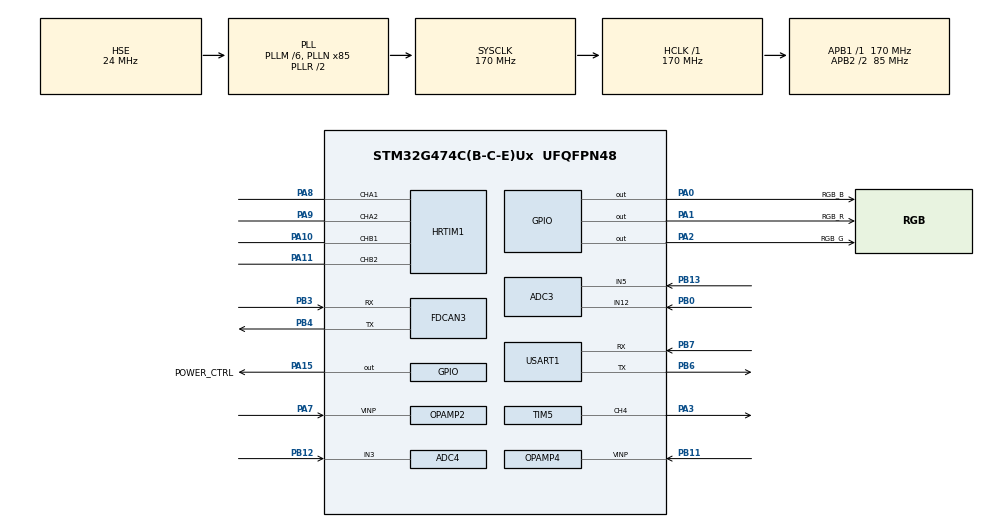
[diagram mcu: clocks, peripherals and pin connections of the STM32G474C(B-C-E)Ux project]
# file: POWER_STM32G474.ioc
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ADC2.Channel-3\#ChannelRegularConversion=ADC_CHANNEL_VOPAMP2
ADC2.ClockPrescaler=ADC_CLOCK_ASYNC_DIV16
ADC2.ContinuousConvMode=DISABLE
ADC2.DMAContinuousRequests=ENABLE
ADC2.ExternalTrigConv=ADC_EXTERNALTRIG_HRTIM_TRG1
ADC2.NbrOfConversion=1
ADC2.NbrOfConversionFlag=1
ADC2.OffsetNumber-3\#ChannelRegularConversion=ADC_OFFSET_NONE
ADC2.OversamplingMode=ENABLE
ADC2.Rank-3\#ChannelRegularConversion=1
ADC2.Ratio=ADC_OVERSAMPLING_RATIO_32
ADC2.RightBitShift=ADC_RIGHTBITSHIFT_5
ADC2.SamplingTime-3\#ChannelRegularConversion=ADC_SAMPLETIME_47CYCLES_5
ADC3.Channel-1\#ChannelRegularConversion=ADC_CHANNEL_5
ADC3.Channel-2\#ChannelRegularConversion=ADC_CHANNEL_12
ADC3.ClockPrescaler=ADC_CLOCK_ASYNC_DIV8
ADC3.ContinuousConvMode=DISABLE
ADC3.DMAContinuousRequests=ENABLE
ADC3.ExternalTrigConv=ADC_EXTERNALTRIG_HRTIM_TRG1
ADC3.NbrOfConversion=2
ADC3.NbrOfConversionFlag=1
ADC3.OffsetNumber-1\#ChannelRegularConversion=ADC_OFFSET_NONE
ADC3.OffsetNumber-2\#ChannelRegularConversion=ADC_OFFSET_NONE
ADC3.OversamplingMode=DISABLE
ADC3.Rank-1\#ChannelRegularConversion=1
ADC3.Rank-2\#ChannelRegularConversion=2
ADC3.SamplingTime-1\#ChannelRegularConversion=ADC_SAMPLETIME_24CYCLES_5
ADC3.SamplingTime-2\#ChannelRegularConversion=ADC_SAMPLETIME_47CYCLES_5
ADC3.master=1
ADC4.Channel-2\#ChannelRegularConversion=ADC_CHANNEL_3
ADC4.ClockPrescaler=ADC_CLOCK_ASYNC_DIV8
ADC4.ContinuousConvMode=DISABLE
ADC4.DMAContinuousRequests=ENABLE
ADC4.ExternalTrigConv=ADC_EXTERNALTRIG_HRTIM_TRG1
ADC4.NbrOfConversionFlag=1
ADC4.OffsetNumber-2\#ChannelRegularConversion=ADC_OFFSET_NONE
ADC4.OversamplingMode=DISABLE
ADC4.Rank-2\#ChannelRegularConversion=1
ADC4.SamplingTime-2\#ChannelRegularConversion=ADC_SAMPLETIME_47CYCLES_5
ADC5.Channel-0\#ChannelRegularConversion=ADC_CHANNEL_VOPAMP4
ADC5.ClockPrescaler=ADC_CLOCK_ASYNC_DIV8
ADC5.ContinuousConvMode=DISABLE
ADC5.DMAContinuousRequests=ENABLE
ADC5.ExternalTrigConv=ADC_EXTERNALTRIG_HRTIM_TRG3
ADC5.NbrOfConversionFlag=1
ADC5.OffsetNumber-0\#ChannelRegularConversion=ADC_OFFSET_NONE
ADC5.OversamplingMode=ENABLE
ADC5.Rank-0\#ChannelRegularConversion=1
ADC5.Ratio=ADC_OVERSAMPLING_RATIO_256
ADC5.RightBitShift=ADC_RIGHTBITSHIFT_7
ADC5.SamplingTime-0\#ChannelRegularConversion=ADC_SAMPLETIME_2CYCLES_5
Dma.ADC2.3.Direction=DMA_PERIPH_TO_MEMORY
Dma.ADC2.3.EventEnable=DISABLE
Dma.ADC2.3.Instance=DMA1_Channel3
Dma.ADC2.3.MemDataAlignment=DMA_MDATAALIGN_HALFWORD
Dma.ADC2.3.MemInc=DMA_MINC_ENABLE
Dma.ADC2.3.Mode=DMA_CIRCULAR
Dma.ADC2.3.PeriphDataAlignment=DMA_PDATAALIGN_HALFWORD
Dma.ADC2.3.PeriphInc=DMA_PINC_DISABLE
Dma.ADC2.3.Polarity=HAL_DMAMUX_REQ_GEN_RISING
Dma.ADC2.3.Priority=DMA_PRIORITY_LOW
Dma.ADC2.3.RequestNumber=1
Dma.ADC2.3.SignalID=NONE
Dma.ADC2.3.SyncEnable=DISABLE
Dma.ADC2.3.SyncPolarity=HAL_DMAMUX_SYNC_NO_EVENT
Dma.ADC2.3.SyncRequestNumber=1
Dma.ADC2.3.SyncSignalID=NONE
Dma.ADC3.0.Direction=DMA_PERIPH_TO_MEMORY
Dma.ADC3.0.EventEnable=DISABLE
Dma.ADC3.0.Instance=DMA1_Channel2
Dma.ADC3.0.MemDataAlignment=DMA_MDATAALIGN_HALFWORD
Dma.ADC3.0.MemInc=DMA_MINC_ENABLE
Dma.ADC3.0.Mode=DMA_CIRCULAR
Dma.ADC3.0.PeriphDataAlignment=DMA_PDATAALIGN_HALFWORD
Dma.ADC3.0.PeriphInc=DMA_PINC_DISABLE
Dma.ADC3.0.Polarity=HAL_DMAMUX_REQ_GEN_RISING
Dma.ADC3.0.Priority=DMA_PRIORITY_LOW
Dma.ADC3.0.RequestNumber=1
Dma.ADC3.0.SignalID=NONE
Dma.ADC3.0.SyncEnable=DISABLE
Dma.ADC3.0.SyncPolarity=HAL_DMAMUX_SYNC_NO_EVENT
Dma.ADC3.0.SyncRequestNumber=1
Dma.ADC3.0.SyncSignalID=NONE
Dma.ADC4.4.Direction=DMA_PERIPH_TO_MEMORY
Dma.ADC4.4.EventEnable=DISABLE
Dma.ADC4.4.Instance=DMA1_Channel4
Dma.ADC4.4.MemDataAlignment=DMA_MDATAALIGN_HALFWORD
Dma.ADC4.4.MemInc=DMA_MINC_ENABLE
Dma.ADC4.4.Mode=DMA_CIRCULAR
Dma.ADC4.4.PeriphDataAlignment=DMA_PDATAALIGN_HALFWORD
Dma.ADC4.4.PeriphInc=DMA_PINC_DISABLE
Dma.ADC4.4.Polarity=HAL_DMAMUX_REQ_GEN_RISING
Dma.ADC4.4.Priority=DMA_PRIORITY_LOW
Dma.ADC4.4.RequestNumber=1
Dma.ADC4.4.SignalID=NONE
Dma.ADC4.4.SyncEnable=DISABLE
Dma.ADC4.4.SyncPolarity=HAL_DMAMUX_SYNC_NO_EVENT
Dma.ADC4.4.SyncRequestNumber=1
Dma.ADC4.4.SyncSignalID=NONE
Dma.ADC5.1.Direction=DMA_PERIPH_TO_MEMORY
Dma.ADC5.1.EventEnable=DISABLE
Dma.ADC5.1.Instance=DMA1_Channel8
Dma.ADC5.1.MemDataAlignment=DMA_MDATAALIGN_WORD
Dma.ADC5.1.MemInc=DMA_MINC_DISABLE
Dma.ADC5.1.Mode=DMA_CIRCULAR
Dma.ADC5.1.PeriphDataAlignment=DMA_PDATAALIGN_WORD
Dma.ADC5.1.PeriphInc=DMA_PINC_DISABLE
Dma.ADC5.1.Polarity=HAL_DMAMUX_REQ_GEN_RISING
Dma.ADC5.1.Priority=DMA_PRIORITY_HIGH
Dma.ADC5.1.RequestNumber=1
Dma.ADC5.1.SignalID=NONE
Dma.ADC5.1.SyncEnable=DISABLE
Dma.ADC5.1.SyncPolarity=HAL_DMAMUX_SYNC_NO_EVENT
Dma.ADC5.1.SyncRequestNumber=1
Dma.ADC5.1.SyncSignalID=NONE
Dma.FMAC_READ.2.Direction=DMA_PERIPH_TO_MEMORY
Dma.FMAC_READ.2.EventEnable=DISABLE
Dma.FMAC_READ.2.Instance=DMA2_Channel1
Dma.FMAC_READ.2.MemDataAlignment=DMA_MDATAALIGN_HALFWORD
Dma.FMAC_READ.2.MemInc=DMA_MINC_DISABLE
Dma.FMAC_READ.2.Mode=DMA_CIRCULAR
Dma.FMAC_READ.2.PeriphDataAlignment=DMA_PDATAALIGN_WORD
Dma.FMAC_READ.2.PeriphInc=DMA_PINC_DISABLE
Dma.FMAC_READ.2.Polarity=HAL_DMAMUX_REQ_GEN_RISING
Dma.FMAC_READ.2.Priority=DMA_PRIORITY_VERY_HIGH
Dma.FMAC_READ.2.RequestNumber=1
Dma.FMAC_READ.2.SignalID=NONE
Dma.FMAC_READ.2.SyncEnable=DISABLE
Dma.FMAC_READ.2.SyncPolarity=HAL_DMAMUX_SYNC_NO_EVENT
Dma.FMAC_READ.2.SyncRequestNumber=1
Dma.FMAC_READ.2.SyncSignalID=NONE
Dma.Request0=ADC3
Dma.Request1=ADC5
Dma.Request2=FMAC_READ
Dma.Request3=ADC2
Dma.Request4=ADC4
FDCAN3.CalculateBaudRateNominal=1000000
FDCAN3.CalculateTimeBitNominal=1000
FDCAN3.CalculateTimeQuantumNominal=100.0
FDCAN3.DataPrescaler=17
FDCAN3.DataSyncJumpWidth=16
FDCAN3.DataTimeSeg1=6
FDCAN3.DataTimeSeg2=3
FDCAN3.ExtFiltersNbr=8
FDCAN3.NominalPrescaler=17
FDCAN3.NominalTimeSeg1=6
FDCAN3.NominalTimeSeg2=3
FDCAN3.StdFiltersNbr=28
HRTIM1.ADCTrigger1_Source1=HRTIM_ADCTRIGGEREVENT13_MASTER_CMP2
HRTIM1.ADCTrigger3_Source1=HRTIM_ADCTRIGGEREVENT13_TIMERB_CMP3
HRTIM1.ADCTrigger_Id1=HRTIM_ADCTRIGGER_1
HRTIM1.ADCTrigger_Id2=__NULL
HRTIM1.ADCTrigger_Id3=HRTIM_ADCTRIGGER_3
HRTIM1.BurstDMAconfig-MasterTimer=__NULL
HRTIM1.CompareUnit1-MasterTimer=HRTIM_COMPAREUNIT_1
HRTIM1.CompareUnit1-Output_TA1TA2=HRTIM_COMPAREUNIT_1
HRTIM1.CompareUnit1-Output_TB1TB2=HRTIM_COMPAREUNIT_1
HRTIM1.CompareUnit2-MasterTimer=HRTIM_COMPAREUNIT_2
HRTIM1.CompareUnit2-Output_TB1TB2=__NULL
HRTIM1.CompareUnit3-MasterTimer=HRTIM_COMPAREUNIT_3
HRTIM1.CompareUnit3-Output_TB1TB2=HRTIM_COMPAREUNIT_3
HRTIM1.CompareUnit4-MasterTimer=__NULL
HRTIM1.CompareValue1-MasterTimer=100
HRTIM1.CompareValue1-Output_TA1TA2=100
HRTIM1.CompareValue1-Output_TB1TB2=100
HRTIM1.CompareValue2-MasterTimer=12920
HRTIM1.CompareValue3-MasterTimer=100
HRTIM1.CompareValue3-Output_TB1TB2=2720
HRTIM1.DeadTimeInsertion-Output_TA1TA2=HRTIM_TIMDEADTIMEINSERTION_ENABLED
HRTIM1.DeadTimeInsertion-Output_TB1TB2=HRTIM_TIMDEADTIMEINSERTION_ENABLED
HRTIM1.Enable=HRTIM_BURSTMODECTL_DISABLED
HRTIM1.FallingValue-Output_TA1TA2=100
HRTIM1.FallingValue-Output_TB1TB2=100
HRTIM1.InterruptRequests1_Master=HRTIM_MASTER_IT_MREP
HRTIM1.NumberADCTriggerSource1=1
HRTIM1.NumberADCTriggerSource3=1
HRTIM1.NumberDMARequests_Master=0
HRTIM1.NumberDMARequests_TA=0
HRTIM1.NumberDMARequests_TB=0
HRTIM1.NumberFaultEnable-Output_TB1TB2=0
HRTIM1.NumberInterruptRequests_Master-MasterTimer=1
HRTIM1.NumberResetSource1-Output_TA1TA2=1
HRTIM1.NumberResetSource1-Output_TB1TB2=1
HRTIM1.NumberResetTrigger-Output_TA1TA2=0
HRTIM1.NumberResetTrigger-Output_TB1TB2=0
HRTIM1.NumberSetSource1-Output_TA1TA2=1
HRTIM1.NumberSetSource1-Output_TB1TB2=1
HRTIM1.NumberUpdateTrigger-Output_TA1TA2=1
HRTIM1.NumberUpdateTrigger-Output_TB1TB2=1
HRTIM1.Periode_MASTER=27200
HRTIM1.Periode_TA=27200
HRTIM1.Periode_TB=27200
HRTIM1.PreloadEnable-MasterTimer=HRTIM_PRELOAD_ENABLED
HRTIM1.PreloadEnable-Output_TA1TA2=HRTIM_PRELOAD_DISABLED
HRTIM1.PreloadEnable-Output_TB1TB2=HRTIM_PRELOAD_ENABLED
HRTIM1.RepetitionUpdate-MasterTimer=HRTIM_UPDATEONREPETITION_ENABLED
HRTIM1.RepetitionUpdate-Output_TA1TA2=HRTIM_UPDATEONREPETITION_DISABLED
HRTIM1.RepetitionUpdate-Output_TB1TB2=HRTIM_UPDATEONREPETITION_ENABLED
HRTIM1.ResetOutput1_Source1-Output_TA1TA2=HRTIM_OUTPUTRESET_TIMCMP1
HRTIM1.ResetOutput1_Source1-Output_TB1TB2=HRTIM_OUTPUTRESET_MASTERCMP3
HRTIM1.RisingValue-Output_TA1TA2=100
HRTIM1.RisingValue-Output_TB1TB2=100
HRTIM1.SetOutput1_Source1-Output_TA1TA2=HRTIM_OUTPUTSET_MASTERCMP1
HRTIM1.SetOutput1_Source1-Output_TB1TB2=HRTIM_OUTPUTSET_TIMCMP1
HRTIM1.SyncOptions=HRTIM_SYNCOPTION_NONE
HRTIM1.UpdateTrigger1-Output_TA1TA2=HRTIM_TIMUPDATETRIGGER_MASTER
HRTIM1.UpdateTrigger1-Output_TB1TB2=HRTIM_TIMUPDATETRIGGER_MASTER
Mcu.Family=STM32G4
Mcu.Name=STM32G474C(B-C-E)Ux
Mcu.Package=UFQFPN48
NVIC.FDCAN3_IT0_IRQn=true\:0\:0\:false\:false\:true\:true\:true\:true
NVIC.HRTIM1_Master_IRQn=true\:1\:0\:true\:false\:true\:true\:true\:true
NVIC.PriorityGroup=NVIC_PRIORITYGROUP_4
NVIC.TIM2_IRQn=true\:0\:0\:true\:false\:true\:true\:true\:true
NVIC.TIM3_IRQn=true\:0\:0\:false\:false\:true\:true\:true\:true
NVIC.TIM4_IRQn=true\:3\:0\:true\:false\:true\:true\:true\:true
OPAMP2.PowerMode=OPAMP_POWERMODE_HIGHSPEED
OPAMP4.PowerMode=OPAMP_POWERMODE_HIGHSPEED
PA0.GPIO_Label=RGB_B
PA0.GPIO_Speed=GPIO_SPEED_FREQ_MEDIUM
PA0.PinState=GPIO_PIN_SET
PA0.Signal=GPIO_Output
PA1.GPIO_Label=RGB_R
PA1.GPIO_Speed=GPIO_SPEED_FREQ_MEDIUM
PA1.PinState=GPIO_PIN_SET
PA1.Signal=GPIO_Output
PA10.GPIO_PuPd=GPIO_PULLDOWN
PA10.Mode=Output_TB1TB2
PA10.Signal=HRTIM1_CHB1
PA11.GPIO_PuPd=GPIO_PULLDOWN
PA11.Mode=Output_TB1TB2
PA11.Signal=HRTIM1_CHB2
PA13.Mode=Serial_Wire
PA13.Signal=SYS_JTMS-SWDIO
PA14.Mode=Serial_Wire
PA14.Signal=SYS_JTCK-SWCLK
PA15.GPIO_Label=POWER_CTRL
PA15.Signal=GPIO_Output
PA2.GPIO_Label=RGB_G
PA2.GPIO_Speed=GPIO_SPEED_FREQ_MEDIUM
PA2.PinState=GPIO_PIN_SET
PA2.Signal=GPIO_Output
PA3.Signal=S_TIM5_CH4
PA7.Mode=Follower_Internally_Connected
PA7.Signal=OPAMP2_VINP
PA8.GPIO_PuPd=GPIO_PULLDOWN
PA8.Mode=Output_TA1TA2
PA8.Signal=HRTIM1_CHA1
PA9.GPIO_PuPd=GPIO_PULLDOWN
PA9.Mode=Output_TA1TA2
PA9.Signal=HRTIM1_CHA2
PB0.Mode=IN12-Single-Ended
PB0.Signal=ADC3_IN12
PB11.Mode=Follower_Internally_Connected
PB11.Signal=OPAMP4_VINP
PB12.Mode=IN3-Single-Ended
PB12.Signal=ADC4_IN3
PB13.Mode=IN5-Single-Ended
PB13.Signal=ADC3_IN5
PB3.Mode=FDCAN_Activate
PB3.Signal=FDCAN3_RX
PB4.Mode=FDCAN_Activate
PB4.Signal=FDCAN3_TX
PB6.Mode=Asynchronous
PB6.Signal=USART1_TX
PB7.Mode=Asynchronous
PB7.Signal=USART1_RX
PF0-OSC_IN.Mode=HSE-External-Oscillator
PF0-OSC_IN.Signal=RCC_OSC_IN
PF1-OSC_OUT.Mode=HSE-External-Oscillator
PF1-OSC_OUT.Signal=RCC_OSC_OUT
ProjectManager.HeapSize=0x1200
ProjectManager.StackSize=0x800
ProjectManager.TargetToolchain=MDK-ARM V5.32
RCC.ADC12CLockSelection=RCC_ADC12CLKSOURCE_PLL
RCC.ADC12Freq_Value=170000000
RCC.ADC345CLockSelection=RCC_ADC345CLKSOURCE_PLL
RCC.ADC345Freq_Value=170000000
RCC.AHBFreq_Value=170000000
RCC.APB1Freq_Value=170000000
RCC.APB1TimFreq_Value=170000000
RCC.APB2CLKDivider=RCC_HCLK_DIV2
RCC.APB2Freq_Value=85000000
RCC.APB2TimFreq_Value=170000000
RCC.CortexFreq_Value=170000000
RCC.EXTERNAL_CLOCK_VALUE=12288000
RCC.HCLKFreq_Value=170000000
RCC.HSE_VALUE=24000000
RCC.HSI48_VALUE=48000000
RCC.HSI_VALUE=16000000
RCC.LSE_VALUE=32768
RCC.PLLM=RCC_PLLM_DIV6
RCC.PLLN=85
RCC.PLLSourceVirtual=RCC_PLLSOURCE_HSE
RCC.SYSCLKFreq_VALUE=170000000
RCC.SYSCLKSource=RCC_SYSCLKSOURCE_PLLCLK
RCC.USBFreq_Value=170000000
RCC.VCOOutputFreq_Value=340000000
SH.S_TIM5_CH4.0=TIM5_CH4,PWM Generation4 CH4
TIM2.AutoReloadPreload=TIM_AUTORELOAD_PRELOAD_ENABLE
TIM2.PeriodNoDither=850000-1
TIM2.TIM_MasterOutputTrigger=TIM_TRGO_RESET
TIM3.PeriodNoDither=19999
TIM3.Prescaler=169
TIM4.PeriodNoDither=999
TIM4.Prescaler=169
TIM5.Channel-PWM\ Generation4\ CH4=TIM_CHANNEL_4
TIM5.PeriodNoDither=19999
USART1.VirtualMode-Asynchronous=VM_ASYNC
VP_ADC2_OPAMP_INTERNAL2.Mode=IN-OPAMP2
VP_ADC5_OPAMP_INTERNAL4.Mode=IN-OPAMP4
VP_FMAC_VS_FMAC.Mode=FMAC_Activate
VP_HRTIM1_VS_hrtimMasterTimerNoOutput.Mode=MasterTimer
VP_SYS_VS_DBSignals.Mode=DisableDeadBatterySignals
VP_TIM2_VS_ClockSourceINT.Mode=Internal
VP_TIM3_VS_ClockSourceINT.Mode=Internal
VP_TIM4_VS_ClockSourceINT.Mode=Internal
VP_TIM5_VS_ClockSourceINT.Mode=Internal
board=custom

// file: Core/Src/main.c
/* USER CODE BEGIN Header */
/**
  ******************************************************************************
  * @file           : main.c
  * @brief          : Main program body
  ******************************************************************************
  * @attention
  *
  * Copyright (c) 2025 STMicroelectronics.
  * All rights reserved.
  *
  * This software is licensed under terms that can be found in the LICENSE file
  * in the root directory of this software component.
  * If no LICENSE file comes with this software, it is provided AS-IS.
  *
  ******************************************************************************
  */
/* USER CODE END Header */
#include "main.h"
#include "adc.h"
#include "dma.h"
#include "fdcan.h"
#include "fmac.h"
#include "hrtim.h"
#include "opamp.h"
#include "tim.h"
#include "usart.h"
#include "gpio.h"

/* USER CODE BEGIN Includes */
#include "fdcan_Init.h"
#include "TIM_Init.h"
/* USER CODE END Includes */

void SystemClock_Config(void);

int main(void)
{

  /* MCU Configuration--------------------------------------------------------*/

  /* Reset of all peripherals, Initializes the Flash interface and the Systick. */
  HAL_Init();

  /* Configure the system clock */
  SystemClock_Config();

  /* Initialize all configured peripherals */
  MX_GPIO_Init();
  MX_DMA_Init();
  MX_HRTIM1_Init();
  MX_FMAC_Init();
  MX_FDCAN3_Init();
  MX_ADC3_Init();
  MX_TIM2_Init();
  MX_TIM5_Init();
  MX_USART1_UART_Init();
  MX_ADC2_Init();
  MX_ADC4_Init();
  MX_OPAMP2_Init();
  MX_TIM3_Init();
  MX_ADC5_Init();
  MX_OPAMP4_Init();
  MX_TIM4_Init();
  /* USER CODE BEGIN 2 */
	vofa_begin();

	Pid_Init();
	OPAMP_Start();
	ADC_init();
	HAL_FMAC_FilterConfig_my();
	FDCAN_Config_Filter();
	HAL_TIM_Base_Start_IT(&htim2);
	HAL_TIM_Base_Start_IT(&htim3);
//	HAL_TIM_Base_Start_IT(&htim4);
    HAL_HRTIM_WaveformCounterStart(&hhrtim1,  HRTIM_TIMERID_MASTER |HRTIM_TIMERID_TIMER_A | HRTIM_TIMERID_TIMER_B);
    HAL_HRTIM_WaveformCounterStart_IT(&hhrtim1, HRTIM_TIMERID_MASTER);

	HAL_TIM_PWM_Start (&htim5 ,TIM_CHANNEL_4);
//	HAL_HRTIM_WaveformOutputStart(&hhrtim1, HRTIM_OUTPUT_TA1|HRTIM_OUTPUT_TA2|HRTIM_OUTPUT_TB1|HRTIM_OUTPUT_TB2); //ͨ����

  /* USER CODE END 2 */

  /* Infinite loop */
  /* USER CODE BEGIN WHILE */
  while (1)
  {

//	HRTIM_DMA_Buffer[0] = (uint16_t)(0.66 * HRTIMAB_Period);//BUCK duty
//    HRTIM_DMA_Buffer[1] = (uint16_t)(0.95 * HRTIMB_Period) >> 1;//ADC sampling trigger
//    HRTIM_DMA_Buffer[2] = (uint16_t)(0.05 * HRTIMAB_Period);//Boost duty
//
//hhrtim1.Instance->sTimerxRegs[0].CMP1xR = 27200*0.5;//ͨ���޸ıȽ�ֵCMP���Ӷ��޸�ռ�ձ�60000
//hhrtim1.Instance->sTimerxRegs[1].CMP1xR = 27200*0.05;//ͨ���޸ıȽ�ֵCMP���Ӷ��޸�ռ�ձ�60000

	  HAL_Delay(1);
    /* USER CODE END WHILE */

  }
}

void SystemClock_Config(void)
{
  RCC_OscInitTypeDef RCC_OscInitStruct = {0};
  RCC_ClkInitTypeDef RCC_ClkInitStruct = {0};

  /** Configure the main internal regulator output voltage
  */
  HAL_PWREx_ControlVoltageScaling(PWR_REGULATOR_VOLTAGE_SCALE1_BOOST);

  /** Initializes the RCC Oscillators according to the specified parameters
  * in the RCC_OscInitTypeDef structure.
  */
  RCC_OscInitStruct.OscillatorType = RCC_OSCILLATORTYPE_HSE;
  RCC_OscInitStruct.HSEState = RCC_HSE_ON;
  RCC_OscInitStruct.PLL.PLLState = RCC_PLL_ON;
  RCC_OscInitStruct.PLL.PLLSource = RCC_PLLSOURCE_HSE;
  RCC_OscInitStruct.PLL.PLLM = RCC_PLLM_DIV6;
  RCC_OscInitStruct.PLL.PLLN = 85;
  RCC_OscInitStruct.PLL.PLLP = RCC_PLLP_DIV2;
  RCC_OscInitStruct.PLL.PLLQ = RCC_PLLQ_DIV2;
  RCC_OscInitStruct.PLL.PLLR = RCC_PLLR_DIV2;
  if (HAL_RCC_OscConfig(&RCC_OscInitStruct) != HAL_OK)
  {
    Error_Handler();
  }

  /** Initializes the CPU, AHB and APB buses clocks
  */
  RCC_ClkInitStruct.ClockType = RCC_CLOCKTYPE_HCLK|RCC_CLOCKTYPE_SYSCLK
                              |RCC_CLOCKTYPE_PCLK1|RCC_CLOCKTYPE_PCLK2;
  RCC_ClkInitStruct.SYSCLKSource = RCC_SYSCLKSOURCE_PLLCLK;
  RCC_ClkInitStruct.AHBCLKDivider = RCC_SYSCLK_DIV1;
  RCC_ClkInitStruct.APB1CLKDivider = RCC_HCLK_DIV1;
  RCC_ClkInitStruct.APB2CLKDivider = RCC_HCLK_DIV2;

  if (HAL_RCC_ClockConfig(&RCC_ClkInitStruct, FLASH_LATENCY_4) != HAL_OK)
  {
    Error_Handler();
  }
}

void Error_Handler(void)
{
  __disable_irq();
  while (1)
  {
  }
}
